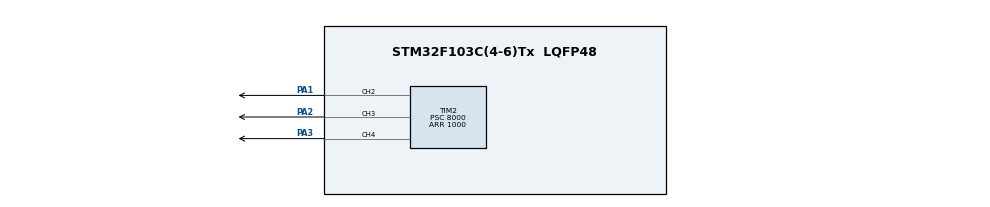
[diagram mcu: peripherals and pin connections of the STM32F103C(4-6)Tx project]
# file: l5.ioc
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Mcu.Family=STM32F1
Mcu.Name=STM32F103C(4-6)Tx
Mcu.Package=LQFP48
NVIC.PriorityGroup=NVIC_PRIORITYGROUP_4
PA1.Signal=S_TIM2_CH2
PA2.Signal=S_TIM2_CH3
PA3.Signal=S_TIM2_CH4
ProjectManager.HeapSize=0x200
ProjectManager.StackSize=0x400
ProjectManager.TargetToolchain=STM32CubeIDE
RCC.APB1Freq_Value=8000000
RCC.APB2Freq_Value=8000000
SH.S_TIM2_CH2.0=TIM2_CH2,PWM Generation2 CH2
SH.S_TIM2_CH3.0=TIM2_CH3,PWM Generation3 CH3
SH.S_TIM2_CH4.0=TIM2_CH4,PWM Generation4 CH4
TIM2.Channel-PWM\ Generation2\ CH2=TIM_CHANNEL_2
TIM2.Channel-PWM\ Generation3\ CH3=TIM_CHANNEL_3
TIM2.Channel-PWM\ Generation4\ CH4=TIM_CHANNEL_4
TIM2.Period=1000
TIM2.Prescaler=8000
TIM2.Pulse-PWM\ Generation2\ CH2=100
TIM2.Pulse-PWM\ Generation3\ CH3=500
TIM2.Pulse-PWM\ Generation4\ CH4=800
VP_TIM2_VS_ClockSourceINT.Mode=Internal
board=custom

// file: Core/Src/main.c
/* USER CODE BEGIN Header */
/**
  ******************************************************************************
  * @file           : main.c
  * @brief          : Main program body
  ******************************************************************************
  * @attention
  *
  * Copyright (c) 2022 STMicroelectronics.
  * All rights reserved.
  *
  * This software is licensed under terms that can be found in the LICENSE file
  * in the root directory of this software component.
  * If no LICENSE file comes with this software, it is provided AS-IS.
  *
  ******************************************************************************
  */
/* USER CODE END Header */
#include "main.h"
#include "tim.h"
#include "gpio.h"

/* USER CODE BEGIN PV */
int myPulsePWM = 0;
  int direction = 0;
/* USER CODE END PV */

void SystemClock_Config(void);

int main(void)
{

  /* MCU Configuration--------------------------------------------------------*/

  /* Reset of all peripherals, Initializes the Flash interface and the Systick. */
  HAL_Init();

  /* Configure the system clock */
  SystemClock_Config();

  /* Initialize all configured peripherals */
  MX_GPIO_Init();
  MX_TIM2_Init();
  HAL_TIM_PWM_Start(&htim2, TIM_CHANNEL_2);
    HAL_TIM_PWM_Start(&htim2, TIM_CHANNEL_3);
    HAL_TIM_PWM_Start(&htim2, TIM_CHANNEL_4);
  /* Infinite loop */
  while (1)
  {

  }
}

void SystemClock_Config(void)
{
  RCC_OscInitTypeDef RCC_OscInitStruct = {0};
  RCC_ClkInitTypeDef RCC_ClkInitStruct = {0};

  /** Initializes the RCC Oscillators according to the specified parameters
  * in the RCC_OscInitTypeDef structure.
  */
  RCC_OscInitStruct.OscillatorType = RCC_OSCILLATORTYPE_HSI;
  RCC_OscInitStruct.HSIState = RCC_HSI_ON;
  RCC_OscInitStruct.HSICalibrationValue = RCC_HSICALIBRATION_DEFAULT;
  RCC_OscInitStruct.PLL.PLLState = RCC_PLL_NONE;
  if (HAL_RCC_OscConfig(&RCC_OscInitStruct) != HAL_OK)
  {
    Error_Handler();
  }

  /** Initializes the CPU, AHB and APB buses clocks
  */
  RCC_ClkInitStruct.ClockType = RCC_CLOCKTYPE_HCLK|RCC_CLOCKTYPE_SYSCLK
                              |RCC_CLOCKTYPE_PCLK1|RCC_CLOCKTYPE_PCLK2;
  RCC_ClkInitStruct.SYSCLKSource = RCC_SYSCLKSOURCE_HSI;
  RCC_ClkInitStruct.AHBCLKDivider = RCC_SYSCLK_DIV1;
  RCC_ClkInitStruct.APB1CLKDivider = RCC_HCLK_DIV1;
  RCC_ClkInitStruct.APB2CLKDivider = RCC_HCLK_DIV1;

  if (HAL_RCC_ClockConfig(&RCC_ClkInitStruct, FLASH_LATENCY_0) != HAL_OK)
  {
    Error_Handler();
  }
}

/* USER CODE BEGIN 4 */
void HAL_TIM_PeriodElapsedCallback(TIM_HandleTypeDef *htim)
{

	if(htim-> Instance == TIM3)
	{
		if(direction == 0)
			  {
				  myPulsePWM += 100;
				  __HAL_TIM_SetCompare(&htim2, TIM_CHANNEL_3, myPulsePWM);
				  if(myPulsePWM == 900)
					  direction = 1;
			  }

		if(direction == 1)
			  {
				  myPulsePWM -= 100;
				  __HAL_TIM_SetCompare(&htim2, TIM_CHANNEL_3, myPulsePWM);
				  if(myPulsePWM == 0)
					  direction = 0;
			  }
	}
}
/* USER CODE END 4 */

void Error_Handler(void)
{
  __disable_irq();
  while (1)
  {
  }
}
